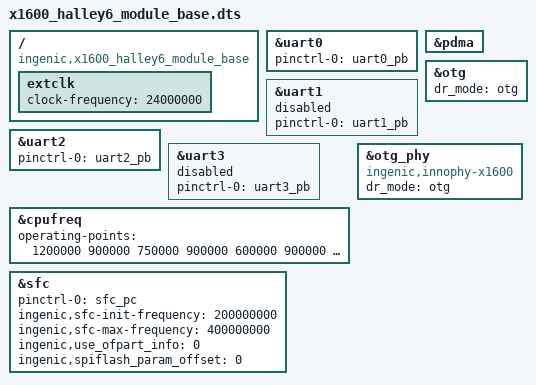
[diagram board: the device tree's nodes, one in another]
/dts-v1/;

#include <dt-bindings/input/input.h>
#include "x1600.dtsi"
#include <dt-bindings/interrupt-controller/irq.h>
#include <generated/autoconf.h>

/ {
	compatible = "ingenic,x1600_halley6_module_base", "ingenic,x1600";
};

&uart0 {
	status = "okay";
	pinctrl-names = "default";
	pinctrl-0 = <&uart0_pb>;
};

&uart1 {
	status = "disable";
	pinctrl-names = "default";
	pinctrl-0 = <&uart1_pb>;
};

&uart2 {
	status = "okay";
	pinctrl-names = "default";
	pinctrl-0 = <&uart2_pb>;
};

&uart3 {
	status = "disable";
	pinctrl-names = "default";
	pinctrl-0 = <&uart3_pb>;
};

&cpufreq {
	status = "okay";
	operating-points = <
		/*KHZ uV */
		1200000	900000
		750000	900000
		600000	900000
		500000	900000
		400000	900000
		375000	900000
		300000	900000
		200000	900000
			>;

};

&pdma {
	status = "okay";
};

&sfc {
	status = "okay";
	pinctrl-names = "default";
	pinctrl-0 = <&sfc_pc>;
	ingenic,sfc-init-frequency = <200000000>;
	ingenic,sfc-max-frequency = <400000000>;
	ingenic,use_ofpart_info  = /bits/ 8 <0>;
	ingenic,spiflash_param_offset = <0>;
};

&otg {
	// g-use-dma;
	dr_mode = "otg";
	status = "okay";
};

&otg_phy {
	dr_mode = "otg";
	compatible = "ingenic,innophy-x1600", "syscon";
	status = "okay";
};


/ {

	extclk: extclk {
		clock-frequency = <24000000>;
	};

	};
